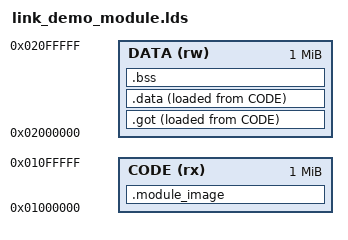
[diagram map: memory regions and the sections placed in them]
/***************************************************************************
 * Copyright (c) 2026 Eclipse ThreadX contributors
 *
 * This program and the accompanying materials are made available under the
 * terms of the MIT License which is available at
 * https://opensource.org/licenses/MIT.
 *
 * AI Disclosure: This file was largely AI-generated by Claude Code (Opus 5).
 * The AI-generated portions may be considered public domain (CC0-1.0)
 * and not subject to the project's licence. The human contributor has
 * reviewed and verified that the code is correct.
 *
 * SPDX-License-Identifier: MIT and CC0-1.0
 **************************************************************************/

/* Link map for the demonstration module alone, for the S32Z280-594EVB.
 *
 * The module is a separate link unit from the manager, and it has to be.  Both
 * sides define the ThreadX API: the kernel defines the real _txe_* entry points
 * and the module library defines shims of the same names that trap into the
 * kernel instead.  Linking them together does not produce a duplicate-symbol
 * error, because the kernel arrives as a static library and the module library
 * as ordinary objects, and an object always beats an archive member.  The module
 * shims therefore win for the whole image, and the manager's own calls to
 * tx_thread_create and friends are quietly redirected into the module.
 *
 * That was not a theory.  It put _txe_thread_create at 0x317F1700, inside the
 * module area, which no kernel MPU region covers -- so tx_application_define
 * called into unmapped memory and the core took a prefetch abort with nothing on
 * the console to say so.
 *
 * POSITION INDEPENDENT, and the two addresses below are fictions
 * ==============================================================
 *
 * The module is built -fpic -msingle-pic-base, so every reference it makes to
 * its own data goes through the global offset table with r9 as the base.  It
 * therefore does not run at the addresses in this file and is not meant to: the
 * two segment origins are nominal, chosen only so that the loader can tell a
 * code address from a data address by comparing against __data_segment_start__.
 * What actually happens at run time is that _gcc_setup rewrites every GOT entry
 * from these nominal addresses to the addresses the manager decided on.
 *
 * That is why they are far apart and why neither is zero.  Far apart, because
 * the whole discrimination is "below the data origin means code"; non-zero,
 * because _gcc_setup treats a zero GOT entry as one the linker never filled in
 * and skips it, so a real address of zero would be silently dropped.
 *
 *   0x01000000  code    preamble, text, rodata, and the load images of the
 *                       GOT and .data -- this is the blob the manager embeds
 *   0x02000000  data    the GOT the module runs against, .data and .bss, all
 *                       of which live in memory the manager allocates
 *
 * The load images matter.  A module's .data cannot be used where it was linked,
 * because the manager never copies it there: _txm_module_manager_internal_load
 * allocates the module's data area from its byte pool and TX_MEMSETs it to zero,
 * and that is the only memory the module is given a region for.  The module's
 * own .data, wherever it was linked, is outside every region the module owns.
 * On silicon that faulted at the first write to an initialised variable, with
 * DFAR pointing into the gap between the granted code and the granted data.
 *
 * So .data and .got have their VMAs in the data segment, where the module will
 * run, and their LMAs in the code segment, inside the blob, where _gcc_setup can
 * find them and copy them out.  AT>CODE is what says that.
 */

MEMORY
{
    /* Nominal.  See the note above: the module runs where the manager puts it,
       not here.  Sized generously because nothing is reserved by being large --
       the raw binary is only as long as the sections actually emitted.  */

    CODE (rx) : ORIGIN = 0x01000000, LENGTH = 0x00100000
    DATA (rw) : ORIGIN = 0x02000000, LENGTH = 0x00100000
}

__code_segment_start__ = 0x01000000;
__data_segment_start__ = 0x02000000;

SECTIONS
{
    /* ---------------------------------------------------------------------
       The code segment, which is the blob byte for byte.
       --------------------------------------------------------------------- */

    .module_image : ALIGN(64)
    {
        __module_image_start__ = .;

        /* The preamble is first because that is where the manager looks for it:
           it reads the properties, the entry points and the two sizes from the
           first words of the image.  KEEP because nothing references it.  */

        KEEP(*(.txm_module_preamble))

        *(.text .text.*)
        *(.glue_7)
        *(.glue_7t)
        *(.rodata .rodata.*)

        . = ALIGN(4);
    } >CODE AT>CODE

    /* ---------------------------------------------------------------------
       The data segment.  VMAs here, load images back in the code segment.
       --------------------------------------------------------------------- */

    /* The GOT, and it must be first in the data segment.  r9 is the GOT base as
       far as the compiler is concerned -- every R_ARM_GOT32 is an offset from
       it -- and the manager sets r9 to txm_module_instance_module_data_base_address,
       which is the start of the module's data area.  So GOT origin and data
       origin have to be the same address, or every offset the compiler emitted
       is measured from the wrong place.  __data_segment_start__ above is that
       address on the nominal side; r9 is that address on the real side, and
       _gcc_setup's rebase is the difference between the two.  */

    .got : ALIGN(4)
    {
        __new_got_start__ = .;
        *(.got.plt)
        *(.igot.plt)
        *(.got)
        __new_got_end__ = .;
    } >DATA AT>CODE

    __got_load_start__ = LOADADDR(.got);

    .data : ALIGN(4)
    {
        __data_start__ = .;
        *(.data .data.*)
        *(.gnu.linkonce.d.*)
        . = ALIGN(4);
        __data_end__ = .;
    } >DATA AT>CODE

    __data_load_start__ = LOADADDR(.data);

    /* NOLOAD, so .bss contributes nothing to the blob.  The manager has already
       zeroed the whole data allocation by the time the module runs -- but
       _gcc_setup zeroes .bss anyway, because "the manager happens to memset it"
       is a property of one loader and not something a module may rely on.  */

    .bss (NOLOAD) : ALIGN(4)
    {
        __bss_start__ = .;
        *(.bss .bss.*)
        *(.gnu.linkonce.b.*)
        *(COMMON)
        . = ALIGN(64);
        __bss_end__ = .;
    } >DATA

    /* ---------------------------------------------------------------------
       The two sizes the preamble declares.
       --------------------------------------------------------------------- */

    /* Code covers everything in the blob, the load images of the GOT and .data
       included, because the module has to be able to read them to copy them out
       and the code region is the only mapping it has over the blob.  Ending it
       at .rodata instead would put the GOT template outside every region the
       module owns and _gcc_setup would fault on its first read.  */

    __txm_module_code_end__  = __data_load_start__ + SIZEOF(.data);
    __txm_module_code_size   = __txm_module_code_end__ - __code_segment_start__;

    /* Data covers the GOT, .data and .bss.  Not the thread stacks: the manager
       adds the start/stop and callback stack sizes to this figure itself, from
       the two stack-size words further down the preamble.  Counting them here
       as well would double them.  */

    __txm_module_data_size   = __bss_end__ - __data_segment_start__;

    /* Unwind tables and toolchain notes would otherwise land at address zero and
       be carried into the raw binary.  A module has no unwinder.

       .rel.dyn and friends are discarded because this is a static link: ld
       resolves every R_ARM_GOT32 itself and writes the finished address into the
       GOT, so there is nothing left for a dynamic loader to do.  If one of these
       ever stops being empty, the assumption above has broken and the module
       needs relocation processing rather than a rebase -- so they are listed
       explicitly, to be found by whoever goes looking.  */

    /DISCARD/ :
    {
        *(.ARM.exidx*)
        *(.ARM.extab*)
        *(.comment)
        *(.note.*)
        *(.dynsym)
        *(.dynstr)
        *(.hash)
        *(.gnu.hash)
        *(.dynamic)
        *(.interp)
        *(.rel.dyn)
        *(.rel.plt)
        *(.plt)
    }
}
